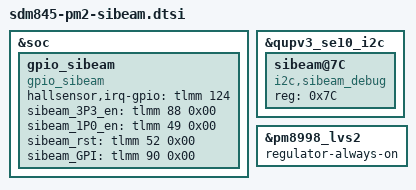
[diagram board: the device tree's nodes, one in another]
&soc {
	gpio_sibeam: gpio_sibeam {
		compatible = "gpio_sibeam";

		hallsensor,irq-gpio = <&tlmm 124 0x00>;
		sibeam_3P3_en = <&tlmm 88 0x00 >;
		sibeam_1P0_en = <&tlmm 49 0x00 >;
		sibeam_rst = <&tlmm 52 0x00>;
		sibeam_GPI = <&tlmm 90 0x00>;
	};
};

&qupv3_se10_i2c {
		status = "ok";
		sibeam@7C {
			compatible = "i2c,sibeam_debug";
			reg = <0x7C>;
		};
};

/* Hall Sensor regulator */
&pm8998_lvs2 {
		regulator-always-on;
};



